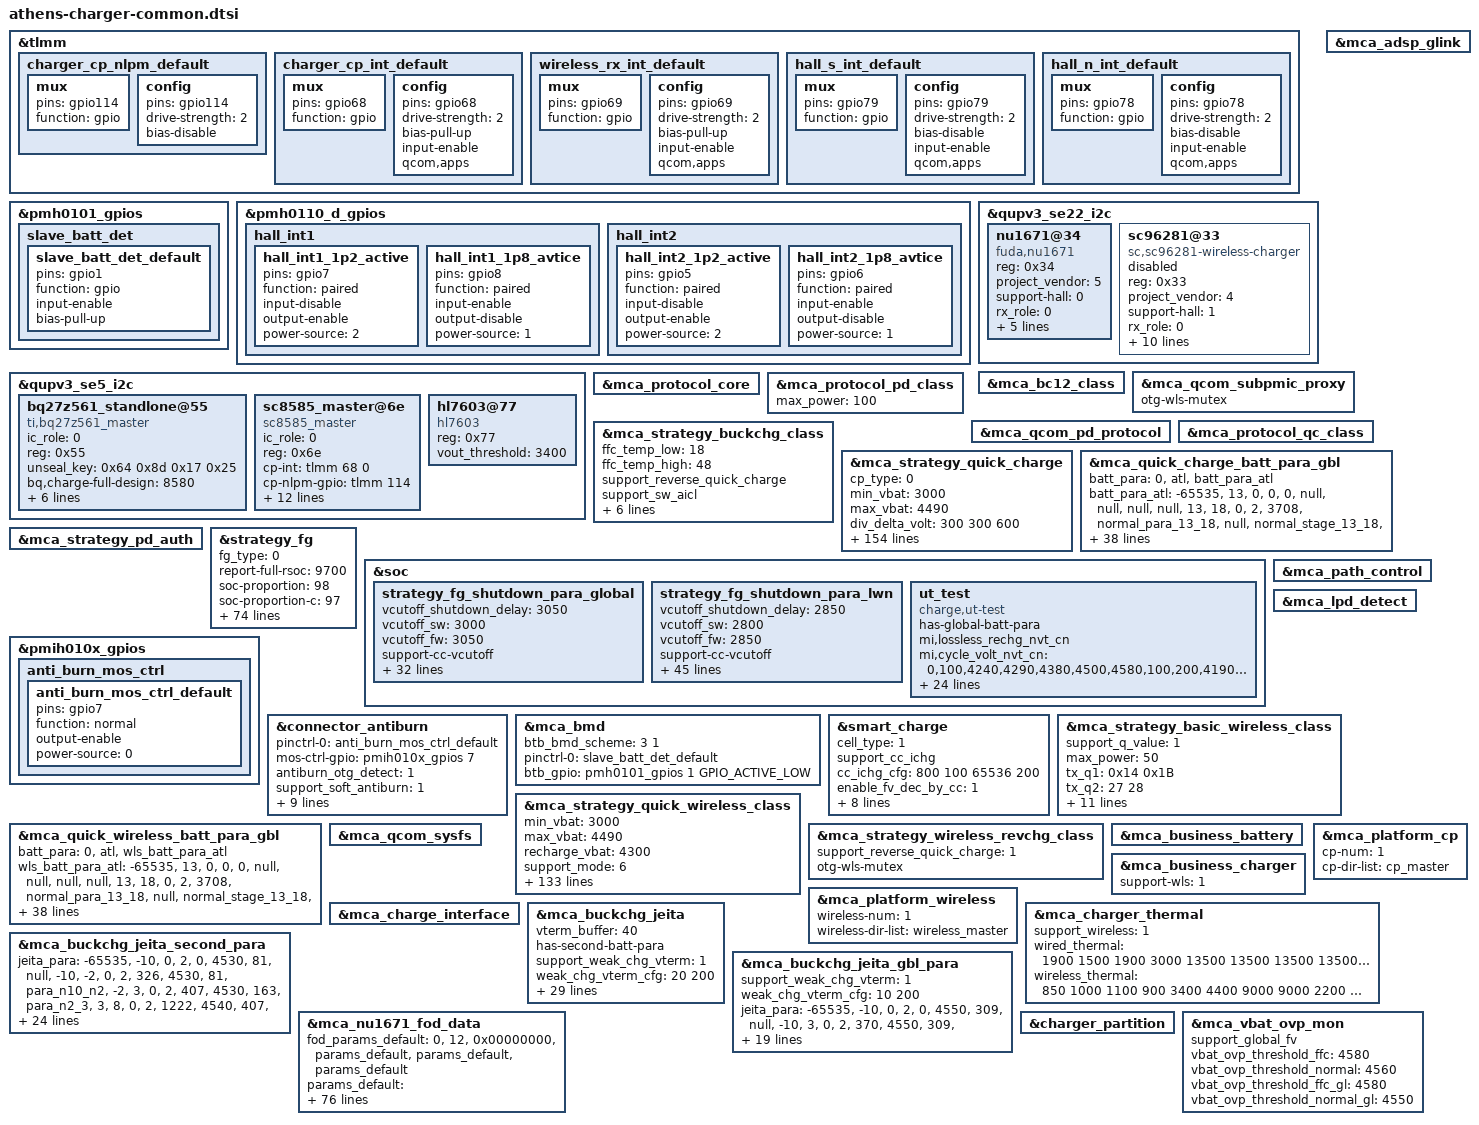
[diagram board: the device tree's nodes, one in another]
#include "mca.dtsi"

&tlmm {
	charger_cp_nlpm_default: charger_cp_nlpm_default {
		mux {
			pins = "gpio114";
			function = "gpio";
		};
		config {
			pins = "gpio114";
			drive-strength = <2>;   /* 2 mA */
			bias-disable;
		};
	};

	charger_cp_int_default: charger_cp_int_default {
		mux {
			pins = "gpio68";
			function = "gpio";
		};
		config {
			pins = "gpio68";
			drive-strength = <2>;   /* 2 mA */
			bias-pull-up;
			input-enable;
			qcom,apps;
		};
	};

	wireless_rx_int_default: wireless_rx_int_default {
		mux {
			pins = "gpio69";
			function = "gpio";
		};

		config {
			pins = "gpio69";
			drive-strength = <2>;
			bias-pull-up;
			input-enable;
			qcom,apps;
		};
	};

	hall_s_int_default: hall_s_int_default {
		mux {
			pins = "gpio79";
			function = "gpio";
		};

		config {
			pins = "gpio79";
			drive-strength = <2>;
			bias-disable;
			input-enable;
			qcom,apps;
		};
	};

	hall_n_int_default: hall_n_int_default {
		mux {
			pins = "gpio78";
			function = "gpio";
		};

		config {
			pins = "gpio78";
			drive-strength = <2>;
			bias-disable;
			input-enable;
			qcom,apps;
		};
	};

};

&pmh0101_gpios {
	slave_batt_det {
		slave_batt_det_default: slave_batt_det_default {
			pins = "gpio1";
			function = "gpio";
			input-enable;
			bias-pull-up;
		};
	};
};

&pmh0110_d_gpios {
	hall_int1 {
		hall_int1_1p2_active: hall_int1_1p2_active {
			pins = "gpio7";
			function = "paired";
			input-disable;
			output-enable;
			power-source = <2>; /* 1.2v */
		};

		hall_int1_1p8_avtice:hall_int1_1p8_avtice {
			pins = "gpio8";
			function = "paired";
			input-enable;
			output-disable;
			power-source = <1>; /* 1.8v */
		};
	};

	hall_int2 {
		hall_int2_1p2_active: hall_int2_1p2_active {
			pins = "gpio5";
			function = "paired";
			input-disable;
			output-enable;
			power-source = <2>; /* 1.2v */
		};

		hall_int2_1p8_avtice:hall_int2_1p8_avtice {
			pins = "gpio6";
			function = "paired";
			input-enable;
			output-disable;
			power-source = <1>; /* 1.8v */
		};
	};
};


&qupv3_se5_i2c {
	status = "ok";
	#address-cells = <1>;
	#size-cells = <0>;
	bq27z561_standlone@55 {
		compatible = "ti,bq27z561_master";
		ic_role = <0>;
		reg = <0x55>;
		unseal_key = /bits/ 8 <0x64 0x8d 0x17 0x25>;
		bq,charge-full-design = <8580>;
		soh_th = <92>;
		cycle_th = <400>;
		cycle_step = <50>;
		resistance-id = <100000>;
		support_batt_manager_4p0;
		support-batt-sn-v2026;
		status = "ok";
	};

	sc8585_master@6e {
		compatible = "sc8585_master";
		status = "ok";
		ic_role = <0>;
		reg = <0x6e>;
		cp-int= <&tlmm 68 0>;
		cp-nlpm-gpio = <&tlmm 114 0x00>;
		pinctrl-names = "default";
		pinctrl-0 = <&charger_cp_nlpm_default>, <&charger_cp_int_default>;
		bat-ovp-threshold = <4700>;
		bat-ovp-alarm-threshold = <4650>;
		bus-ovp-threshold = <21000 12000 6000>;
		usb-ovp-threshold = <21000 14000 7500>;
		bus-ocp-threshold = <5000 5500 5000>;
		wpc-ovp-threshold = <21000>;
		out-ovp-threshold = <5000>;
		pmid2-uvp-threshold = <150 350 100>;
		pmid2-ovp-threshold = <600>;
		ucp-fall-dg = <32000>;
	};

	hl7603@77 {
		compatible = "hl7603";
		reg = <0x77>;
		vout_threshold = <3400>;
	};
};

&qupv3_se22_i2c {
	status = "ok";
	#address-cells = <1>;
	#size-cells = <0>;

	nu1671@34 {
		compatible = "fuda,nu1671";
		reg = <0x34>;
		project_vendor = <5>;
		support-hall = <0>;
		rx_role = <0>;
		fw_version_index = <3>;
		pinctrl-names = "default";
		pinctrl-0 = <&wireless_rx_int_default>;
		rx-int = <&tlmm 69 0x00>;
		pwr-det-int = <&tlmm 57 0x00>;
		sleep-rx-gpio = <&tlmm 200 0x00>;
	};

	sc96281@33 {
		status = "disabled";
		compatible = "sc,sc96281-wireless-charger";
		reg = <0x33>;
		project_vendor = <4>;
		support-hall = <1>;
		rx_role = <0>;
		fw_version_index = <1>;
		pinctrl-names = "default";
		pinctrl-0 = <&wireless_rx_int_default>, <&hall_s_int_default>, <&hall_n_int_default>,
					<&hall_int1_1p2_active>, <&hall_int1_1p8_avtice>,
					<&hall_int2_1p2_active>, <&hall_int2_1p8_avtice>;
		rx-int = <&tlmm 69 0x00>;
		pwr-det-int = <&tlmm 57 0x00>;
		sleep-rx-gpio = <&tlmm 200 0x00>;
		hall-s-int = <&tlmm 79 0x00>;
		hall-n-int = <&tlmm 78 0x00>;
	};
};

&mca_adsp_glink {
	status = "ok";
};

&mca_bc12_class {
	status = "ok";
};

&mca_qcom_subpmic_proxy {
	status = "ok";
	otg-wls-mutex;
};

&mca_protocol_core {
	status = "ok";
};

&mca_protocol_pd_class {
	status = "ok";
	max_power = <100>;
};

&mca_qcom_pd_protocol {
	status = "ok";
};

&mca_protocol_qc_class {
	status = "ok";
};


&mca_strategy_buckchg_class {
	status = "ok";
	ffc_temp_low = <18>;
	ffc_temp_high = <48>;
	support_reverse_quick_charge;
	support_sw_aicl;
	support_revchg_screenon;
	support_pps_100w = <3>;
	support_revchg_27w;
	revchg_soc_thr = <60>;
	/* BS(Battery Sense) Vacc enable. Params inherited from mca.dtsi. */
	support_pmic_vacc;
	ffc_terminated_by_cp = <1>;
};

&mca_strategy_quick_charge {
	status = "ok";
	cp_type = <0>;
	min_vbat = <3000>;
	max_vbat = <4490>;
	div_delta_volt = <300 300 600>;
	div_single_curr = <4500 11000 18400>;
	div_max_curr = <5000 12000 18400>;
	non_mi_pps_max_curr = <4500 11000 18400>;
	support_mode = <6>;
	has-global-batt-para;
	support_cp_vfc = <1>;
	real_curr_max = <17500>;
	support_monitor_current = <17600>;
	curr_monitor_time_s = <120>;
	support_cancel_compensation;
	max_vbat_threshold = <4580>;
	en_buck_parallel_chg = <1>;
	buck_icl_fcc_curr = <1000 3000>;
	buck_en_th = <13000 2500>;
	buck_dis_th = <13000 3850>;
	cp_switch_pmic_th = <1000>;
	drop_fv_value = <10>; /* BS strategy -10mv, drop fv value for BS */

	/* BS(Battery Sense) PMIC&CP dynamic parallel charging (wired) enable.
	 * Params (pdc_*, enable_cp_para_pdc, ...) inherited from mca.dtsi.
	 */
	drop_fv_cycle_pdc = <65535>;
	support_pmic_dynamic_chg;

	use-terminate-staged;
	curr_terminate_hys = <300>;
	terminate_staged_para =
		<110 1000>,
		<105 3000>;
	vfc_iout_fsw_map =
		"6000", "720",
		"0", "420";
	batt_depolarize_time_s = <60>;

	/* volt_ratio, cur_gap, vbat_gap, vstep_ratio */
	vstep_para =
		"1", "300", "2000", "0", "2",
		"2", "300", "2000", "0", "4",
		"4", "300", "8000", "0", "25",
		"4", "300", "4000", "20", "17",
		"4", "300", "2000", "10", "5",
		"4", "300", "1200", "10", "5",
		"4", "300", "800", "0", "2",
		"1", "800", "2000", "0", "2",
		"2", "800", "2000", "0", "4",
		"4", "800", "8000", "0", "10",
		"4", "800", "6000", "0", "5",
		"4", "800", "4000", "0", "2";

	batt_para =
		"0", "atl", "batt_para_atl",
		"0", "lwn", "batt_para_lwn";
	/* temp_low, temp_high, low_hys, high_hys, max_curr, normal_para, ffc_para, normal_stage, ffc_stage */
	batt_para_atl =
		"-65535", "13", "0", "0", "0", "null", "null", "null", "null",
		"13", "15", "0", "1", "3258", "normal_para_atl_13_15", "null", "normal_stage_atl_13_15", "null",
		"15", "18", "0", "1", "8960", "normal_para_atl_15_18", "null", "null", "null",
		"18", "23", "0", "1", "12218", "normal_para_atl_18_23", "ffc_para_atl_18_23", "normal_stage_atl_18_23", "ffc_stage_atl_18_23",
		"23", "25", "0", "0", "18300", "normal_para_atl_23_25", "ffc_para_atl_23_25", "normal_stage_atl_18_23", "ffc_stage_atl_23_25",
		"25", "35", "0", "0", "18300", "normal_para_atl_25_35", "ffc_para_atl_25_35", "normal_stage_atl_18_23", "ffc_stage_atl_25_35",
		"35", "40", "1", "0", "18300", "normal_para_atl_35_40", "ffc_para_atl_35_40", "normal_stage_atl_18_23", "ffc_stage_atl_35_40",
		"40", "48", "1", "0", "18300", "normal_para_atl_40_48", "ffc_para_atl_40_48", "normal_stage_atl_18_23", "ffc_stage_atl_40_48",
		"48", "65535", "2", "0", "0", "null", "null", "null", "null";

	/* volt, curr_max, curr_min */
	normal_para_atl_13_15 =
		"3900", "3258", "1629",
		"4553", "1629", "407";
	normal_stage_atl_13_15 = <0 1 0 0>;

	normal_para_atl_15_18 =
		"3900", "8960", "6516",
		"4150", "6516", "3258",
		"4250", "3258", "1629",
		"4553", "1629", "407";

	normal_para_atl_18_23 =
		"3900", "12218", "8960",
		"4000", "8960", "6516",
		"4150", "6516", "3258",
		"4250", "3258", "1629",
		"4543", "1629", "407";
	normal_stage_atl_18_23 = <0 1 0 0 0 0 0 0 0 0>;
	ffc_para_atl_18_23 =
		"3900", "12218", "8960",
		"4000", "8960", "6516",
		"4150", "6516", "3258",
		"4250", "3258", "1629",
		"4570", "1629", "781";
	ffc_stage_atl_18_23 = <0 1 0 0 0 0 0 0 0 0>;

	normal_para_atl_23_25 =
		"4240", "18300", "12400",
		"4290", "12400", "8145",
		"4350", "8145", "6516",
		"4450", "6516", "4887",
		"4543", "4887", "407";
	ffc_para_atl_23_25 =
		"4240", "18300", "12400",
		"4290", "12400", "8145",
		"4350", "8145", "6516",
		"4450", "6516", "4887",
		"4570", "4887", "1064";
	ffc_stage_atl_23_25 = <0 1 0 0 0 0 0 0 0 0>;

	normal_para_atl_25_35 =
		"4240", "18300", "12400",
		"4290", "12400", "9774",
		"4380", "9774", "8145",
		"4480", "8145", "6516",
		"4543", "6516", "407";
	ffc_para_atl_25_35 =
		"4240", "18300", "12400",
		"4290", "12400", "9774",
		"4380", "9774", "8145",
		"4500", "8145", "6516",
		"4570", "6516", "1064";
	ffc_stage_atl_25_35 = <0 1 0 0 0 0 0 0 0 0>;

	normal_para_atl_35_40 =
		"4240", "18300", "12400",
		"4290", "12400", "9774",
		"4380", "9774", "8145",
		"4480", "8145", "6516",
		"4513", "6516", "407";
	ffc_para_atl_35_40 =
		"4240", "18300", "12400",
		"4290", "12400", "9774",
		"4380", "9774", "8145",
		"4500", "8145", "6516",
		"4570", "6516", "1751";
	ffc_stage_atl_35_40 = <0 1 0 0 0 0 0 0 0 0>;

	normal_para_atl_40_48 =
		"4240", "18300", "12400",
		"4290", "12400", "9774",
		"4380", "9774", "8145",
		"4480", "8145", "6516",
		"4503", "6516", "407";
	ffc_para_atl_40_48 =
		"4240", "18300", "12400",
		"4290", "12400", "9774",
		"4380", "9774", "8145",
		"4500", "8145", "6516",
		"4570", "6516", "3043";
	ffc_stage_atl_40_48 = <0 1 0 0 0 0 0 0 0 0>;

	batt_para_lwn =
		"-65535", "13", "0", "0", "0", "null", "null", "null", "null",
		"13", "15", "0", "1", "3258", "normal_para_lwn_13_15", "null", "normal_stage_lwn_13_15", "null",
		"15", "18", "0", "1", "8960", "normal_para_lwn_15_18", "null", "null", "null",
		"18", "23", "0", "1", "12218", "normal_para_lwn_18_23", "ffc_para_lwn_18_23", "normal_stage_lwn_18_23", "ffc_stage_lwn_18_23",
		"23", "25", "0", "0", "18300", "normal_para_lwn_23_25", "ffc_para_lwn_23_25", "normal_stage_lwn_18_23", "ffc_stage_lwn_23_25",
		"25", "35", "0", "0", "18300", "normal_para_lwn_25_35", "ffc_para_lwn_25_35", "normal_stage_lwn_18_23", "ffc_stage_lwn_25_35",
		"35", "40", "1", "0", "18300", "normal_para_lwn_35_40", "ffc_para_lwn_35_40", "normal_stage_lwn_18_23", "ffc_stage_lwn_35_40",
		"40", "48", "1", "0", "18300", "normal_para_lwn_40_48", "ffc_para_lwn_40_48", "normal_stage_lwn_18_23", "ffc_stage_lwn_40_48",
		"48", "65535", "2", "0", "0", "null", "null", "null", "null";
	/* volt, curr_max, curr_min */
	normal_para_lwn_13_15 =
		"3900", "3258", "1629",
		"4533", "1629", "407";
	normal_stage_lwn_13_15 = <0 1 0 0>;

	normal_para_lwn_15_18 =
		"3900", "8960", "6516",
		"4150", "6516", "3258",
		"4250", "3258", "1629",
		"4533", "1629", "407";

	normal_para_lwn_18_23 =
		"3900", "12218", "8960",
		"4000", "8960", "6516",
		"4150", "6516", "3258",
		"4250", "3258", "1629",
		"4513", "1629", "407";
	normal_stage_lwn_18_23 = <0 1 0 0 0 0 0 0 0 0>;
	ffc_para_lwn_18_23 =
		"3900", "12218", "8960",
		"4000", "8960", "6516",
		"4150", "6516", "3258",
		"4250", "3258", "1629",
		"4560", "1629", "977";
	ffc_stage_lwn_18_23 = <0 1 0 0 0 0 0 0 0 0>;

	normal_para_lwn_23_25 =
		"4190", "18300", "12400",
		"4270", "12400", "8145",
		"4350", "8145", "6516",
		"4500", "6516", "4887",
		"4513", "4887", "407";
	ffc_para_lwn_23_25 =
		"4190", "18300", "12400",
		"4270", "12400", "8145",
		"4350", "8145", "6516",
		"4500", "6516", "4887",
		"4560", "4887", "1140";
	ffc_stage_lwn_23_25 = <0 1 0 0 0 0 0 0 0 0>;

	normal_para_lwn_25_35 =
		"4190", "18300", "12400",
		"4270", "12400", "9774",
		"4350", "9774", "8145",
		"4500", "8145", "6516",
		"4513", "6516", "407";
	ffc_para_lwn_25_35 =
		"4190", "18300", "12400",
		"4270", "12400", "9774",
		"4350", "9774", "8145",
		"4500", "8145", "6516",
		"4560", "6516", "1140";
	ffc_stage_lwn_25_35 = <0 1 0 0 0 0 0 0 0 0>;

	normal_para_lwn_35_40 =
		"4190", "18300", "12400",
		"4270", "12400", "9774",
		"4350", "9774", "8145",
		"4480", "8145", "6516",
		"4493", "6516", "407";
	ffc_para_lwn_35_40 =
		"4190", "18300", "12400",
		"4270", "12400", "9774",
		"4350", "9774", "8145",
		"4500", "8145", "6516",
		"4560", "6516", "1792";
	ffc_stage_lwn_35_40 = <0 1 0 0 0 0 0 0 0 0>;

	normal_para_lwn_40_48 =
		"4190", "18300", "12400",
		"4270", "12400", "9774",
		"4350", "9774", "8145",
		"4470", "8145", "6516",
		"4483", "6516", "407";
	ffc_para_lwn_40_48 =
		"4190", "18300", "12400",
		"4270", "12400", "9774",
		"4350", "9774", "8145",
		"4500", "8145", "6516",
		"4560", "6516", "3095";
	ffc_stage_lwn_40_48 = <0 1 0 0 0 0 0 0 0 0>;
};

&mca_quick_charge_batt_para_gbl {
	batt_para =
		"0", "atl", "batt_para_atl";
	/* temp_low, temp_high, low_hys, high_hys, max_curr, normal_para, ffc_para, normal_stage, ffc_stage */
	batt_para_atl =
		"-65535", "13", "0", "0", "0", "null", "null", "null", "null",
		"13", "18", "0", "2", "3708", "normal_para_13_18", "null", "normal_stage_13_18", "null",
		"18", "23", "0", "1", "12360", "normal_para_18_23", "ffc_para_18_23", "normal_stage_13_18", "ffc_stage_18_23",
		"23", "35", "0", "0", "18100", "normal_para_23_35", "ffc_para_23_35", "normal_stage_13_18", "ffc_stage_23_35",
		"35", "40", "1", "0", "18100", "normal_para_35_40", "ffc_para_35_40", "normal_stage_13_18", "ffc_stage_35_40",
		"40", "48", "1", "0", "18100", "normal_para_40_48", "ffc_para_40_48", "normal_stage_13_18", "ffc_stage_40_48",
		"48", "65535", "2", "0", "0", "null", "null", "null", "null";

	/* volt, curr_max, curr_min */
	normal_para_13_18 =
		"4200", "3708", "2472",
		"4543", "2472", "432";
	normal_stage_13_18 = <0 1 0 0>;

	normal_para_18_23 =
		"4250", "12360", "7416",
		"4523", "7416", "432";
	ffc_para_18_23 =
		"4250", "12360", "9270",
		"4500", "9270", "7416",
		"4573", "7416", "1050";
	ffc_stage_18_23 = <0 1 0 0 0 0>;

	normal_para_23_35 =
		"4230", "18100", "7416",
		"4523", "7416", "432";
	ffc_para_23_35 =
		"4230", "18100", "12400",
		"4330", "12400", "11124",
		"4400", "11124", "9270",
		"4500", "9270", "7416",
		"4573", "7416", "1668";
	ffc_stage_23_35 = <0 1 0 0 0 0 0 0 0 0>;

	normal_para_35_40 =
		"4230", "18100", "7416",
		"4513", "7416", "432";
	ffc_para_35_40 =
		"4230", "18100", "12400",
		"4330", "12400", "11124",
		"4400", "11124", "9270",
		"4500", "9270", "7416",
		"4573", "7416", "2720";
	ffc_stage_35_40 = <0 1 0 0 0 0 0 0 0 0>;

	normal_para_40_48 =
		"4230", "18100", "7416",
		"4503", "7416", "432";
	ffc_para_40_48 =
		"4230", "18100", "12400",
		"4330", "12400", "11124",
		"4400", "11124", "9270",
		"4500", "9270", "7416",
		"4573", "7416", "4264";
	ffc_stage_40_48 = <0 1 0 0 0 0 0 0 0 0>;
};

&mca_strategy_pd_auth {
	status = "ok";
};

&strategy_fg {
	status = "ok";
	fg_type = <0>;
	report-full-rsoc = <9700>;
	soc-proportion = <98>;
	soc-proportion-c = <97>;
	support-pnc;
	support-vpack-low-shutdown;
	has_global_shutdown_para;
	has_second_supplier_para;
	vcutoff_shutdown_delay = <2850>;
	vcutoff_sw = <2800>;
	vcutoff_fw = <2850>;
	vterm_delta = <7>;
	clear_CC_per_hundred = <0>;

	/* BS(Battery Sense) Vacc + CP dynamic enable. Params inherited from mca.dtsi. */
	support_pmic_vacc;
	support_pmic_cp_dynamic;

	support-cc-vcutoff;
	/* temp_low, temp_high, low_temp_hys, high_temp_hys, vterm_para_name */
	cc_vcutoff_cfg =
		"-65535", "-6", "0", "2", "cc_para0",
		"-6", "0", "2", "2", "cc_para1",
		"0", "10", "2", "2", "cc_para2",
		"10", "60", "2", "0", "cc_para3",
		"60", "65535", "2", "0", "cc_para4";
	/* cycle_count, vterm_fw, vterm_shutdown_delay, vempty */
	cc_para0 =
		"300", "2650", "2600", "2500",
		"500", "2650", "2600", "2550",
		"1100", "2750", "2700", "2650",
		"1300", "3000", "2950", "2900",
		"65535", "3050", "3000", "2950";
	cc_para1 =
		"300", "2650", "2600", "2550",
		"500", "2750", "2700", "2650",
		"1100", "2850", "2800", "2750",
		"1300", "3050", "3000", "2950",
		"65535", "3100", "3050", "3000";
	cc_para2 =
		"300", "2650", "2650", "2600",
		"500", "2900", "2900", "2850",
		"1100", "2950", "2950", "2900",
		"1300", "3100", "3100", "3050",
		"65535", "3150", "3150", "3100";
	cc_para3 =
		"300", "2850", "2850", "2800",
		"500", "3010", "3010", "2960",
		"1100", "3070", "3070", "3020",
		"1300", "3200", "3200", "3150",
		"65535", "3230", "3230", "3180";
	cc_para4 =
		"65535", "3230", "3230", "3180";

	support-dod-vcutoff-v2;
	weight = <17 13 10>;
	/* temp_low, temp_high, low_temp_hys, high_temp_hys, vterm_para_name */
	dod_vcutoff_cfg =
		"-65535", "-6", "0", "2", "dod_para0",
		"-6", "0", "2", "2", "dod_para1",
		"0", "10", "2", "2", "dod_para2",
		"10", "60", "2", "0", "dod_para3",
		"60", "65535", "2", "0", "dod_para4";
	/* dod_count, vterm_fw, vterm_shutdown_delay, vempty */
	dod_para0 =
		"187", "2650", "2600", "2500",
		"363", "2650", "2600", "2550",
		"671", "2750", "2700", "2650",
		"825", "3000", "2950", "2900",
		"65535", "3050", "3000", "2950";
	dod_para1 =
		"187", "2650", "2600", "2550",
		"363", "2750", "2700", "2650",
		"671", "2850", "2800", "2750",
		"825", "3050", "3000", "2950",
		"65535", "3050", "3000", "2950";
	dod_para2 =
		"187", "2650", "2650", "2600",
		"363", "2900", "2900", "2850",
		"671", "2950", "2950", "2900",
		"825", "3100", "3100", "3050",
		"65535", "3100", "3100", "3050";
	dod_para3 =
		"187", "2850", "2850", "2800",
		"363", "3010", "3010", "2960",
		"671", "3070", "3070", "3020",
		"825", "3200", "3200", "3150",
		"65535", "3230", "3230", "3180";
	dod_para4 =
		"65535", "3230", "3230", "3180";

	adapt_power = <100>;
	model-name = "Q11_8580mah_100w";
	model-name-global = "Q11_6330mah_100w";
	support_full_design_gl;
	charge-full-design = <8580>;
	support_dynamic_capacity_comp;
	support_dtpt = <1>;
	charge-full-design-gl = <6330>;
	fg_hightemp_vterm = <4200>;
	support-lossless-rechg = <1>;
	lossless_rechg_cfg = <18 47 300>;
	lossless-rechg-nor = <0>;
	support_normal_force_full;
	normal_force_full_hys = <116>;
	support_clear_cycle;
	suppot_RSOC_0_smooth = <1>;
	smooth_temp_unit = <0 150>; //15℃
	smooth_curr_unit = <0 300000 600000 1000000 >;
	smooth_vol_offset = <0x80000000 0 100 200 300 >;
	dischg_smooth_low_temp_unit = <
		10 10 10 10
		20 10 10 10
		40 20 10 10
		80 40 30 20
		150 80 70 50 >;
	dischg_smooth_high_temp_unit = <
		10 10 10 10
		30 20 10 10
		60 40 20 10
		150 70 50 40
		200 150 100 70 >;
	support_extreme_cold = <2>;
	extreme_cold_temp_compemsation =
		"2147483647", "50", "100",
		"2147483647", "600", "80";
};

&soc {
	strategy_fg_shutdown_para_global {
		vcutoff_shutdown_delay = <3050>;
		vcutoff_sw = <3000>;
		vcutoff_fw = <3050>;
		support-cc-vcutoff;
		/* temp_low, temp_high, low_temp_hys, high_temp_hys, vterm_para_name */
		cc_vcutoff_cfg =
			"-65535", "-6", "0", "2", "cc_para0",
			"-6", "0", "2", "2", "cc_para1",
			"0", "10", "2", "2", "cc_para2",
			"10", "60", "2", "0", "cc_para3",
			"60", "65535", "2", "0", "cc_para4";
		/* cycle_count, vterm_fw, vterm_shutdown_delay, vempty */
		cc_para0 =
			"800", "2900", "2850", "2800",
			"1200", "2900", "2850", "2800",
			"65535", "2900", "2850","2800";
		cc_para1 =
			"800", "2900", "2850", "2800",
			"1200", "2900", "2850", "2800",
			"65535", "3000", "2950","2900";
		cc_para2 =
			"800", "2900", "2900", "2850",
			"1200", "3000", "3000", "2950",
			"65535", "3050", "3050","3000";
		cc_para3 =
			"800", "3050", "3050", "3000",
			"1200", "3120", "3120", "3070",
			"65535", "3200", "3200","3150";
		cc_para4 =
			"65535", "3200", "3200","3150";
		support-dod-vcutoff-v2;
		weight = <20 18 15>;
		/* temp_low, temp_high, low_temp_hys, high_temp_hys, vterm_para_name */
		dod_vcutoff_cfg =
			"-65535", "-6", "0", "2", "dod_para0",
			"-6", "0", "2", "2", "dod_para1",
			"0", "10", "2", "2", "dod_para2",
			"10", "60", "2", "0", "dod_para3",
			"60", "65535", "2", "0", "dod_para4";
		/* dod_count, vterm_fw, vterm_shutdown_delay, vempty */
		dod_para0 =
			"169", "2900", "2850", "2800",
			"452", "2900", "2850", "2800",
			"1051", "2900", "2850", "2800",
			"65535", "3000", "2950", "2900";
		dod_para1 =
			"169", "2900", "2850", "2800",
			"452", "2900", "2850", "2800",
			"1051", "3000", "2950", "2900",
			"65535", "3050", "3000", "2950";
		dod_para2 =
			"169", "2900", "2900", "2850",
			"452", "3000", "3000", "2950",
			"1051", "3050", "3050", "3000",
			"65535", "3150", "3150", "3100";
		dod_para3 =
			"169", "3050", "3050", "3000",
			"452", "3120", "3120", "3070",
			"1051", "3200", "3200", "3150",
			"65535", "3250", "3250", "3200";
		dod_para4 =
			"65535", "3250", "3250", "3200";
	};

	strategy_fg_shutdown_para_lwn {
		vcutoff_shutdown_delay = <2850>;
		vcutoff_sw = <2800>;
		vcutoff_fw = <2850>;
		support-cc-vcutoff;
		cc_vcutoff_cfg =
			"-65535", "-6", "0", "2", "cc_para0_lwn",
			"-6", "0", "2", "2", "cc_para1_lwn",
			"0", "10", "2", "2", "cc_para2_lwn",
			"10", "60", "2", "0", "cc_para3_lwn",
			"60", "65535", "2", "0", "cc_para4_lwn";
		cc_para0_lwn =
			"300", "2600", "2550", "2500",
			"500", "2650", "2600", "2550",
			"1100", "2750", "2700", "2650",
			"1300", "2800", "2750", "2700",
			"65535", "3000", "2950", "2900";
		cc_para1_lwn =
			"300", "2650", "2600", "2550",
			"500", "2750", "2700", "2650",
			"1100", "2850", "2800", "2750",
			"1300", "2900", "2850", "2800",
			"65535", "3050", "3000", "3050";
		cc_para2_lwn =
			"300", "2700", "2700", "2650",
			"500", "2850", "2850", "2800",
			"1100", "2950", "2950", "2900",
			"1300", "3000", "3000", "2950",
			"65535", "3150", "3150", "3050";
		cc_para3_lwn =
			"300", "2850", "2850", "2800",
			"500", "3010", "3010", "2960",
			"1100", "3080", "3080", "3030",
			"1300", "3160", "3160", "3110",
			"65535", "3210", "3210", "3160";
		cc_para4_lwn =
			"65535", "3210", "3210", "3160";
		support-dod-vcutoff-v2;
		weight = <21 19 15>;
		dod_vcutoff_cfg =
			"-65535", "-6", "0", "2", "dod_para0_lwn",
			"-6", "0", "2", "2", "dod_para1_lwn",
			"0", "10", "2", "2", "dod_para2_lwn",
			"10", "60", "2", "0", "dod_para3_lwn",
			"60", "65535", "2", "0", "dod_para4_lwn";
		dod_para0_lwn =
			"59", "2600", "2550", "2500",
			"152", "2650", "2600", "2550",
			"718", "2750", "2700", "2650",
			"1370", "2800", "2750", "2700",
			"65535", "3000", "2950", "2900";
		dod_para1_lwn =
			"59", "2650", "2600", "2550",
			"152", "2750", "2700", "2650",
			"718", "2850", "2800", "2750",
			"1370", "2900", "2850", "2800",
			"65535", "3050", "3000", "2950";
		dod_para2_lwn =
			"59", "2700", "2700", "2650",
			"152", "2850", "2850", "2800",
			"718", "2950", "2950", "2900",
			"1370", "3000", "3000", "2950",
			"65535", "3150", "3150", "3050";
		dod_para3_lwn =
			"59", "2850", "2850", "2800",
			"152", "3010", "3010", "2960",
			"718", "3080", "3080", "3030",
			"1370", "3160", "3160", "3110",
			"65535", "3210", "3210", "3160";
		dod_para4_lwn =
			"65535", "3210", "3210", "3160";
	};
};

&pmih010x_gpios {
	anti_burn_mos_ctrl {
		anti_burn_mos_ctrl_default: anti_burn_mos_ctrl_default {
			pins = "gpio7";
			function = "normal";
			output-enable;
			//drive-strength = <2>;
			power-source = <0>;
		};
	};
};

&connector_antiburn {
	status = "ok";
	pinctrl-names = "default";
	pinctrl-0 = <&anti_burn_mos_ctrl_default>;
	mos-ctrl-gpio = <&pmih010x_gpios 7 0>;
	antiburn_otg_detect = <1>;
	support_soft_antiburn = <1>;
	support_hw_antiburn = <1>;
	use_double_ntc = <1>;
	monitor_interval = <1000>;
	thermal-zone-name = "conn_therm";
	thermal-zone-name2 = "conn_therm2";
	max_temp_increase_rate = <4>; /*ntc temperature increase speed per second.*/
	otg_boost_src = <0>; /* BOOST_SRC_EXTERNAL */
	en_src = <0>; /* OTG_EN_BOOST */
	thermal-board-temp-name = "board_sensor_therm";
};

&mca_bmd {
	status = "ok";
	btb_bmd_scheme = <3 1>;
	pinctrl-names = "default";
	pinctrl-0 = <&slave_batt_det_default>;
	btb_gpio = <&pmh0101_gpios 1 GPIO_ACTIVE_LOW>;
};

&smart_charge {
	status = "ok";
	cell_type = <1>;
	support_cc_ichg;
	/* cyclecount delta_ichg*/
	cc_ichg_cfg = <
		800 100
		65536 200>;
	enable_fv_dec_by_cc = <1>;
	smart_bypass_support = <1>;
	smart_bypass_entry_soc = <40>;
	smart_bypass_high_lmt_cfg = <
		(-100) 150 5 5 4500
		151 200 5 5 4500
		201	250	5 5 4500
		251	300	5 5 3500
		301	370	5 5 2500
		371	800	5 5 1000>;
	smart_bypass_med_lmt_cfg = <
		(-100) 150 5 5 18400
		151	200	5 5 18400
		201	250	5 5 18400
		251	300	5 5 8000
		301	370	5 5 5000
		371	800	5 5 2000>;
	smart_bypass_low_lmt_cfg = <
		(-100) 150 5 5 18400
		151	200	5 5 18400
		201	250	5 5 18400
		251	300	5 5 9000
		301	370	5 5 5000
		371	800	5 5 3000>;
};

&mca_path_control {
	status = "ok";
};

&mca_lpd_detect {
	status = "ok";
};

&mca_strategy_basic_wireless_class {
	status = "ok";
	support_q_value = <1>;
	max_power = <50>;
	/* low_inductance_tx_50w, low_inductance_tx_80w */
	tx_q1 = /bits/ 8 <0x14 0x1B>;
	tx_q2 = <27 28>;
	rx_max_iout = <2650 2650>;
	wls_vdd_src = <4>;
	ffc_temp_low = <15>;
	ffc_temp_high = <48>;
	support-hall = <0>;

	support-dynamic-cp = <1>;
	dynamic-cp-uuid = <0x09010A01>;
	dynamic-cp-min-tx-adapter = <14>;
	dynamic-cp-4to2-threshold = <6000>;
	dynamic-cp-2-1-max-fcc = <9200>;

	/* BS(Battery Sense) Vacc for wireless. */
	support_pmic_vacc;
};

&mca_strategy_quick_wireless_class {
	status = "ok";
	min_vbat = <3000>;
	max_vbat = <4490>;
	recharge_vbat = <4300>;
	support_mode = <6>;
	div_single_curr = <0 9200 9200>;
	div_max_curr = <0 9200 9200>;
	has-global-batt-para;
	support-hall = <0>;
	exit_fcc = <1000 1500 1500>;

	/* BS(Battery Sense) PMIC&CP dynamic parallel charging (wireless) enable.
	 * Params (exit_fcc, pdc_*, cp_ovp_spec_pdc, ...) inherited from mca.dtsi.
	 */
	support_pmic_dynamic_chg;

	batt_para =
		"0", "atl", "wls_batt_para_atl",
		"0", "lwn", "wls_batt_para_lwn";
	/* temp_low, temp_high, low_temp_hys, high_temp_hys, max_current, volt_para_name stage_para_name*/
	wls_batt_para_atl =
		"-65535", "13", "0", "0", "0", "null", "null", "null", "null",
		"13", "15", "0", "1", "3258", "normal_para_atl_13_15", "null", "normal_stage_atl_13_15", "null",
		"15", "18", "0", "1", "8960", "normal_para_atl_15_18", "null", "null", "null",
		"18", "23", "0", "1", "12218", "normal_para_atl_18_23", "ffc_para_atl_18_23", "normal_stage_atl_18_23", "ffc_stage_atl_18_23",
		"23", "25", "0", "0", "17600", "normal_para_atl_23_25", "ffc_para_atl_23_25", "normal_stage_atl_18_23", "ffc_stage_atl_23_25",
		"25", "35", "0", "0", "17600", "normal_para_atl_25_35", "ffc_para_atl_25_35", "normal_stage_atl_18_23", "ffc_stage_atl_25_35",
		"35", "40", "1", "0", "17600", "normal_para_atl_35_40", "ffc_para_atl_35_40", "normal_stage_atl_18_23", "ffc_stage_atl_35_40",
		"40", "48", "1", "0", "17600", "normal_para_atl_40_48", "ffc_para_atl_40_48", "normal_stage_atl_18_23", "ffc_stage_atl_40_48",
		"48", "65535", "2", "0", "0", "null", "null", "null", "null";

	/* volt, curr_max, curr_min */
	normal_para_atl_13_15 =
		"3900", "3258", "1629",
		"4553", "1629", "407";
	normal_stage_atl_13_15 = <0 1 0 0>;

	normal_para_atl_15_18 =
		"3900", "8960", "6516",
		"4150", "6516", "3258",
		"4250", "3258", "1629",
		"4553", "1629", "407";

	normal_para_atl_18_23 =
		"3900", "12218", "8960",
		"4000", "8960", "6516",
		"4150", "6516", "3258",
		"4250", "3258", "1629",
		"4543", "1629", "407";
	normal_stage_atl_18_23 = <0 1 0 0 0 0 0 0 0 0>;
	ffc_para_atl_18_23 =
		"3900", "12218", "8960",
		"4000", "8960", "6516",
		"4150", "6516", "3258",
		"4250", "3258", "1629",
		"4540", "1629", "781";
	ffc_stage_atl_18_23 = <0 1 0 1 0 1 0 1 0 1>;

	normal_para_atl_23_25 =
		"4240", "17600", "12400",
		"4290", "12400", "8145",
		"4380", "8145", "6516",
		"4500", "6516", "4887",
		"4543", "4887", "407";
	ffc_para_atl_23_25 =
		"4240", "17600", "12400",
		"4290", "12400", "8145",
		"4380", "8145", "6516",
		"4500", "6516", "4887",
		"4540", "4887", "1064";
	ffc_stage_atl_23_25 = <0 1 0 1 0 1 0 1 0 1>;

	normal_para_atl_25_35 =
		"4240", "17600", "12400",
		"4290", "12400", "9774",
		"4380", "9774", "8145",
		"4500", "8145", "6516",
		"4543", "6516", "407";
	ffc_para_atl_25_35 =
		"4240", "17600", "12400",
		"4290", "12400", "9774",
		"4380", "9774", "8145",
		"4500", "8145", "6516",
		"4540", "6516", "1064";
	ffc_stage_atl_25_35 = <0 1 0 1 0 1 0 1 0 1>;

	normal_para_atl_35_40 =
		"4240", "17600", "12400",
		"4290", "12400", "9774",
		"4380", "9774", "8145",
		"4500", "8145", "6516",
		"4513", "6516", "407";
	ffc_para_atl_35_40 =
		"4240", "17600", "12400",
		"4290", "12400", "9774",
		"4380", "9774", "8145",
		"4500", "8145", "6516",
		"4510", "6516", "1751";
	ffc_stage_atl_35_40 = <0 1 0 1 0 1 0 1 0 1>;

	normal_para_atl_40_48 =
		"4240", "17600", "12400",
		"4290", "12400", "9774",
		"4380", "9774", "8145",
		"4500", "8145", "6516",
		"4503", "6516", "407";
	ffc_para_atl_40_48 =
		"4240", "17600", "12400",
		"4290", "12400", "9774",
		"4380", "9774", "6516",
		"4500", "6516", "3043";
	ffc_stage_atl_40_48 = <0 1 0 1 0 1 0 1 0 1>;

	wls_batt_para_lwn =
		"-65535", "13", "0", "0", "0", "null", "null", "null", "null",
		"13", "15", "0", "1", "3258", "normal_para_lwn_13_15", "null", "normal_stage_lwn_13_15", "null",
		"15", "18", "0", "1", "8960", "normal_para_lwn_15_18", "null", "null", "null",
		"18", "23", "0", "1", "12218", "normal_para_lwn_18_23", "ffc_para_lwn_18_23", "normal_stage_lwn_18_23", "ffc_stage_lwn_18_23",
		"23", "25", "0", "0", "17600", "normal_para_lwn_23_25", "ffc_para_lwn_23_25", "normal_stage_lwn_18_23", "ffc_stage_lwn_23_25",
		"25", "35", "0", "0", "17600", "normal_para_lwn_25_35", "ffc_para_lwn_25_35", "normal_stage_lwn_18_23", "ffc_stage_lwn_25_35",
		"35", "40", "1", "0", "17600", "normal_para_lwn_35_40", "ffc_para_lwn_35_40", "normal_stage_lwn_18_23", "ffc_stage_lwn_35_40",
		"40", "48", "1", "0", "17600", "normal_para_lwn_40_48", "ffc_para_lwn_40_48", "normal_stage_lwn_18_23", "ffc_stage_lwn_40_48",
		"48", "65535", "2", "0", "0", "null", "null", "null", "null";
	/* volt, curr_max, curr_min */
	normal_para_lwn_13_15 =
		"3900", "3258", "1629",
		"4533", "1629", "407";
	normal_stage_lwn_13_15 = <0 1 0 0>;

	normal_para_lwn_15_18 =
		"3900", "8960", "6516",
		"4150", "6516", "3258",
		"4250", "3258", "1629",
		"4533", "1629", "407";

	normal_para_lwn_18_23 =
		"3900", "12218", "8960",
		"4000", "8960", "6516",
		"4150", "6516", "3258",
		"4250", "3258", "1629",
		"4513", "1629", "407";
	normal_stage_lwn_18_23 = <0 1 0 0 0 0 0 0 0 0>;
	ffc_para_lwn_18_23 =
		"3900", "12218", "8960",
		"4000", "8960", "6516",
		"4150", "6516", "3258",
		"4250", "3258", "1629",
		"4510", "1629", "896";
	ffc_stage_lwn_18_23 = <0 1 0 1 0 1 0 1 0 1>;

	normal_para_lwn_23_25 =
		"4190", "17600", "12400",
		"4270", "12400", "8145",
		"4350", "8145", "6516",
		"4500", "6516", "4887",
		"4513", "4887", "407";
	ffc_para_lwn_23_25 =
		"4190", "17600", "12400",
		"4270", "12400", "8145",
		"4350", "8145", "6516",
		"4500", "6516", "4887",
		"4510", "4887", "1222";
	ffc_stage_lwn_23_25 = <0 1 0 1 0 1 0 1 0 1>;

	normal_para_lwn_25_35 =
		"4190", "17600", "12400",
		"4270", "12400", "9774",
		"4350", "9774", "8145",
		"4500", "8145", "6516",
		"4513", "6516", "407";
	ffc_para_lwn_25_35 =
		"4190", "17600", "12400",
		"4270", "12400", "9774",
		"4350", "9774", "8145",
		"4500", "8145", "6516",
		"4510", "6516", "1222";
	ffc_stage_lwn_25_35 = <0 1 0 1 0 1 0 1 0 1>;

	normal_para_lwn_35_40 =
		"4190", "17600", "12400",
		"4270", "12400", "9774",
		"4350", "9774", "8145",
		"4480", "8145", "6516",
		"4493", "6516", "407";
	ffc_para_lwn_35_40 =
		"4190", "17600", "12400",
		"4270", "12400", "9774",
		"4350", "9774", "6516",
		"4490", "6516", "1955";
	ffc_stage_lwn_35_40 = <0 1 0 1 0 1 0 1 0 1>;

	normal_para_lwn_40_48 =
		"4190", "17600", "12400",
		"4270", "12400", "9774",
		"4350", "9774", "8145",
		"4470", "8145", "6516",
		"4483", "6516", "407";
	ffc_para_lwn_40_48 =
		"4190", "17600", "12400",
		"4270", "12400", "9774",
		"4350", "9774", "6516",
		"4480", "6516", "3258";
	ffc_stage_lwn_40_48 = <0 1 0 1 0 1 0 1 0 1>;

	vstep_para =
		"1", "2000", "2",
		"2", "4000", "25",
		"2", "3000", "25",
		"2", "2000", "4",
		"4", "4000", "25",
		"4", "3000", "25",
		"4", "2000", "6",
		"4", "1000", "3",
		"4", "500", "2",
		"4", "200", "1";
};

&mca_quick_wireless_batt_para_gbl {
	batt_para =
		"0", "atl", "wls_batt_para_atl";
	/* temp_low, temp_high, low_temp_hys, high_temp_hys, max_current, volt_para_name stage_para_name*/
	wls_batt_para_atl =
		"-65535", "13", "0", "0", "0", "null", "null", "null", "null",
		"13", "18", "0", "2", "3708", "normal_para_13_18", "null", "normal_stage_13_18", "null",
		"18", "23", "0", "1", "12360", "normal_para_18_23", "ffc_para_18_23", "normal_stage_13_18", "ffc_stage_18_23",
		"23", "35", "0", "0", "17600", "normal_para_23_35", "ffc_para_23_35", "normal_stage_13_18", "ffc_stage_23_35",
		"35", "40", "1", "0", "17600", "normal_para_35_40", "ffc_para_35_40", "normal_stage_13_18", "ffc_stage_35_40",
		"40", "48", "1", "0", "17600", "normal_para_40_48", "ffc_para_40_48", "normal_stage_13_18", "ffc_stage_40_48",
		"48", "65535", "2", "0", "0", "null", "null", "null", "null";

	/* volt, curr_max, curr_min */
	normal_para_13_18 =
		"4200", "3708", "2472",
		"4543", "2472", "432";
	normal_stage_13_18 = <0 1 0 0>;

	normal_para_18_23 =
		"4250", "12360", "7416",
		"4523", "7416", "432";
	ffc_para_18_23 =
		"4250", "12360", "9270",
		"4500", "9270", "7416",
		"4573", "7416", "1050";
	ffc_stage_18_23 = <0 1 0 0 0 0>;

	normal_para_23_35 =
		"4230", "17600", "7416",
		"4523", "7416", "432";
	ffc_para_23_35 =
		"4230", "17600", "12400",
		"4330", "12400", "11124",
		"4400", "11124", "9270",
		"4500", "9270", "7416",
		"4573", "7416", "1668";
	ffc_stage_23_35 = <0 1 0 0 0 0 0 0 0 0>;

	normal_para_35_40 =
		"4230", "17600", "7416",
		"4513", "7416", "432";
	ffc_para_35_40 =
		"4230", "17600", "12400",
		"4330", "12400", "11124",
		"4400", "11124", "9270",
		"4500", "9270", "7416",
		"4573", "7416", "2720";
	ffc_stage_35_40 = <0 1 0 0 0 0 0 0 0 0>;

	normal_para_40_48 =
		"4230", "17600", "7416",
		"4503", "7416", "432";
	ffc_para_40_48 =
		"4230", "17600", "12400",
		"4330", "12400", "11124",
		"4400", "11124", "9270",
		"4500", "9270", "7416",
		"4573", "7416", "4264";
	ffc_stage_40_48 = <0 1 0 0 0 0 0 0 0 0>;
};

&mca_strategy_wireless_revchg_class {
	status = "ok";
	support_reverse_quick_charge = <1>;
	otg-wls-mutex;
};

&mca_qcom_sysfs {
	status = "ok";
};

&mca_business_battery {
	status = "ok";
};

&mca_business_charger {
	support-wls = <1>;
	status = "ok";
};

&mca_platform_cp {
	status = "ok";
	cp-num = <1>;
	cp-dir-list = "cp_master";
};

&mca_platform_wireless {
	status = "ok";
	wireless-num = <1>;
	wireless-dir-list = "wireless_master";
};

&mca_charge_interface {
	status = "ok";
};

&mca_charger_thermal {
	status = "ok";
	support_wireless = <1>;
	/* 5v_in 9v_in 5v_ichg 9v_ichg div1_single div1_multi div2_single div2_multi div4_single div4_multi*/
	wired_thermal = <
		1900 1500 1900 3000 13500 13500 13500 13500 13500 13500 /* level 1 */
		1900 1500 1900 3000 11000 11000 11000 11000 11000 11000 /* level 2 */
		1900 1500 1900 3000 9000  9000  9000  9000  9000  9000  /* level 3 */
		1900 1450 1900 3000 8000  8000  8000  8000  8000  8000  /* level 4 */
		1900 1400 1900 3000 7000  7000  7000  7000  7000  7000  /* level 5 */
		1900 1350 1900 2800 6000  6000  6000  6000  6000  6000  /* level 6 */
		1900 1300 1900 2600 5000  5000  5000  5000  5000  5000  /* level 7 */
		1900 1150 1900 2310 4000  4000  4000  4000  4000  4000  /* level 8 */
		1700 1100 1700 2200 3500  3500  3500  3500  3500  3500  /* level 9 */
		1600 1000 1600 2000 3000  3000  3000  3000  3000  3000  /* level 10 */
		1400 900  1500 2000 2500  2500  2500  2500  2500  2500  /* level 11 */
		1200 850  1500 2000 2000  2000  2000  2000  2000  2000  /* level 12 */
		1100 750  1500 1500 1500  1500  1500  1500  1500  1500  /* level 13 */
		1100 650  1000 1000 1000  1000  1000  1000  1000  1000  /* level 14 */
		1100 600  500  500  500   500   500   500   500   500   /* level 15 */
	>;
	/* bpp_in bpp_qc2 bpp_qc3 epp_in cp_20w cp_30w cp_50w cp_80w voice_box magnet_30w xiaomi_car */
	wireless_thermal = <
		850 1000 1100 900 3400 4400 9000 9000 2200 4400 9000  /* level 1 */
		850 1000 1100 750 3200 4200 8000 8000 2200 4200 8000  /* level 2 */
		850 1000 1100 650 2200 3400 7000 7000 1000 3400 7000  /* level 3 */
		700 1000 1100 650 1800 2800 6000 6000 1000 2800 6000  /* level 4 */
		700 1000  700 650 1500 2600 5000 5000  800 2600 5000  /* level 5 */
		500 1000  700 650 1300 2200 4000 4000  800 2200 4000  /* level 6 */
		500  700  600 400 1100 2200 3500 3500  700 2200 3500  /* level 7 */
		500  700  600 400 1000 1800 3000 3000  700 1800 3000  /* level 8 */
		500  500  500 300  800 1100 2500 2500  600 1100 2500  /* level 9 */
		400  500  500 300  700 1000 2000 2000  600 1000 2000  /* level 10 */
		400  500  500 250  600  800 1500 1500  500  800 1500  /* level 11 */
		400  500  500 250  500  700 1000 1000  500  700 1000  /* level 12 */
		300  500  500 250  500  600  800  800  400  600  800   /* level 13 */
		300  400  400 200  400  500  500  500  400  500  500   /* level 14 */
		300  300  300 150  300  300  300  300  300  300  300   /* level 15 */
	>;
};

&mca_buckchg_jeita {
	status = "ok";
	vterm_buffer = <40>;
	has-second-batt-para;
	support_weak_chg_vterm = <1>;
	weak_chg_vterm_cfg = <20 200>;
	has-global-batt-para;
	/* temp_low, temp_high, low_temp_hys, high_temp_hys, max_current, vterm, iterm volt_para_name */
	jeita_para =
		"-65535", "-10", "0", "2", "0", "4550", "81", "null",
		"-10", "-2", "0", "2", "326", "4550", "81", "para_n10_n2",
		"-2", "3", "0", "2", "407", "4550", "163", "para_n2_3",
		"3", "8", "0", "2", "652", "4550", "163", "para_3_8",
		"8", "13", "0", "2", "1629", "4560", "407", "para_8_13",
		"13", "15", "0", "1", "3258", "4560", "407", "para_13_15",
		"15", "18", "0", "1", "8960", "4560", "407", "para_15_18",
		"18", "23", "0", "1", "12218", "4550", "407", "null",
		"23", "25", "0", "0", "18300", "4550", "407", "null",
		"25", "35", "0", "0", "18300", "4550", "407", "null",
		"35", "40", "1", "0", "18300", "4520", "407", "null",
		"40", "48", "1", "0", "18300", "4510", "407", "null",
		"48", "55", "2", "0", "4073", "4080", "407", "null",
		"55", "65535", "2", "2", "0", "4080", "407", "null";
	para_n10_n2 =
		"3900", "326",
		"4550", "163";
	para_n2_3 =
		"3900", "407",
		"4550", "326";
	para_3_8 =
		"3900", "652",
		"4550", "407";
	para_8_13 =
		"3900", "1629",
		"4560", "815";
	para_13_15 =
		"3900", "3258",
		"4560", "1629";
	para_15_18 =
		"3900", "8960",
		"4150", "6516",
		"4250", "3258",
		"4560", "1629";
	jeita_para_ffc =
		"18", "23", "0", "1", "12218", "4580", "781", "null",
		"23", "25", "0", "0", "18300", "4580", "1064", "null",
		"25", "35", "0", "0", "18300", "4580", "1064", "null",
		"35", "40", "1", "0", "18300", "4580", "1751", "null",
		"40", "48", "1", "0", "18300", "4580", "3043", "null",
		"48", "55", "2", "0", "4073", "4080", "407", "null",
		"55", "65535", "2", "2", "0", "4080", "407", "null";
};

&mca_buckchg_jeita_second_para {
	/* temp_low, temp_high, low_temp_hys, high_temp_hys, max_current, vterm, iterm volt_para_name */
	jeita_para =
		"-65535", "-10", "0", "2", "0", "4530", "81", "null",
		"-10", "-2", "0", "2", "326", "4530", "81", "para_n10_n2",
		"-2", "3", "0", "2", "407", "4530", "163", "para_n2_3",
		"3", "8", "0", "2", "1222", "4540", "407", "para_3_8",
		"8", "13", "0", "2", "1629", "4540", "407", "para_8_13",
		"13", "15", "0", "1", "3258", "4540", "407", "para_13_15",
		"15", "18", "0", "1", "8960", "4540", "407", "para_15_18",
		"18", "23", "0", "1", "12218", "4520", "407", "null",
		"23", "25", "0", "0", "18300", "4520", "407", "null",
		"25", "35", "0", "0", "18300", "4520", "407", "null",
		"35", "40", "1", "0", "18300", "4500", "407", "null",
		"40", "48", "1", "0", "18300", "4490", "407", "null",
		"48", "55", "2", "0", "4073", "4080", "407", "null",
		"55", "65535", "2", "2", "0", "4080", "407", "null";
	para_n10_n2 =
		"3900", "326",
		"4530", "163";
	para_n2_3 =
		"3900", "407",
		"4530", "326";
	para_3_8 =
		"3900", "1222",
		"4540", "815";
	para_8_13 =
		"3900", "1629",
		"4540", "815";
	para_13_15 =
		"3900", "3258",
		"4540", "1629";
	para_15_18 =
		"3900", "8960",
		"4150", "6516",
		"4250", "3258",
		"4540", "1629";
	jeita_para_ffc =
		"18", "23", "0", "1", "12218", "4570", "977", "null",
		"23", "25", "0", "0", "17600", "4570", "1140", "null",
		"25", "35", "0", "0", "17600", "4570", "1140", "null",
		"35", "40", "1", "0", "17600", "4570", "1792", "null",
		"40", "48", "1", "0", "18300", "4570", "3095", "null",
		"48", "55", "2", "0", "4073", "4080", "407", "null",
		"55", "65535", "2", "2", "0", "4080", "407", "null";
};

&mca_buckchg_jeita_gbl_para {
	support_weak_chg_vterm = <1>;
	weak_chg_vterm_cfg = <10 200>;
	/* temp_low, temp_high, low_temp_hys, high_temp_hys, max_current, vterm, iterm volt_para_name */
	jeita_para =
		"-65535", "-10", "0", "2", "0", "4550", "309", "null",
		"-10", "3", "0", "2", "370", "4550", "309", "para_n10_3",
		"3", "8", "0", "2", "927", "4550", "432", "para_3_8",
		"8", "13", "0", "2", "1854", "4550", "432", "para_8_13",
		"13", "18", "0", "2", "3708", "4550", "432", "para_13_18",
		"18", "23", "0", "1", "12360", "4530", "432", "null",
		"23", "35", "0", "0", "18100", "4530", "432", "null",
		"35", "40", "1", "0", "18100", "4520", "432", "null",
		"40", "48", "1", "0", "18100", "4510", "432", "null",
		"48", "55", "2", "0", "3090", "4080", "432", "null",
		"55", "65535", "2", "2", "0", "4080", "432", "null";
	para_n10_3 =
		"4550", "370";
	para_3_8 =
		"4200", "927",
		"4550", "618";
	para_8_13 =
		"4200", "1854",
		"4550", "1236";
	para_13_18 =
		"4200", "3708",
		"4550", "2472";
	jeita_para_ffc =
		"18", "23", "0", "1", "12360", "4580", "1050", "null",
		"23", "35", "0", "0", "18100", "4580", "1668", "null",
		"35", "40", "1", "0", "18100", "4580", "2720", "null",
		"40", "48", "1", "0", "18100", "4580", "4264", "null",
		"48", "55", "2", "0", "3090", "4080", "432", "null",
		"55", "65535", "2", "2", "0", "4080", "432", "null";
};

&mca_nu1671_fod_data {
	/* type, length, uuid, params_no_mag, params_mag_thin, params_mag_thick */
	fod_params_default =
		"0", "12", "0x00000000", "params_default", "params_default", "params_default";
	params_default = /bits/ 8 <
		10  40
		10  40
		10  40
		8   47
		7   46
		7   53
		7   47
		7   49
		7   48
		7   46
		7   46
		7   46
	>;

	/* type, length, uuid, params_no_mag, params_mag_thin, params_mag_thick */
	fod_params_bpp_plus =
		"2", "7",  "0x00000000", "params_bpp_plus", "params_bpp_plus", "params_bpp_plus";
	params_bpp_plus = /bits/ 8 <
		10  50
		10  50
		8   50
		8   50
		8   50
		8   50
		8   50
	>;

	fod_params_2_1 =
		"1", "20", "0x09010A01", "params_m2_50W_2_1", "params_m2_50W_2_1", "params_m2_50W_2_1",
		"1", "20", "0x09010305", "params_n1_80W_2_1", "params_n1_80W_2_1", "params_n1_80W_2_1";
	/* gain, offset */
	params_m2_50W_2_1 = /bits/ 8 <
		0 27
		0 35
		0 30
		0 36
		0 36
		0 28
		0 6
		1 6
		1 7
		1 7
		1 5
		1 6
		2 6
		2 6
		2 11
		2 14
		2 28
		2 36
		2 36
		2 38
	>;

	params_n1_80W_2_1 = /bits/ 8 <
		0 18
		0 14
		0 11
		0 12
		0 11
		0 17
		0 14
		1 12
		1 16
		1 18
		1 20
		1 20
		2 16
		2 16
		2 20
		2 22
		2 25
		2 31
		2 31
		2 33
	>;


	/* type, length, uuid, params_no_mag, params_mag_thin, params_mag_thick */
	fod_params =
		"1", "20", "0x09010901", "params_l2_50W", "params_l2_50W", "params_l2_50W",
		"0", "12", "0x09010A01", "params_m2_50W", "params_m2_50W", "params_m2_50W",
		"1", "20", "0x09010904", "params_k1_80W", "params_k1_80W", "params_k1_80W",
		"1", "20", "0x0901090C", "params_k8_100W", "params_k8_100W", "params_k8_100W",
		"0", "12", "0x09010305", "params_n1_80W", "params_n1_80W", "params_n1_80W",
		"1", "20", "0x09010A07", "params_double_coil_30W", "params_double_coil_30W", "params_double_coil_30W",
		"2", "7",  "0x01020B03", "params_trx_rev_22P5W", "params_trx_rev_22P5W", "params_trx_rev_22P5W",
		"1", "20", "0x0901010B", "params_j1s_55W", "params_j1s_55W", "params_j1s_55W",
		"1", "20", "0x09080108", "params_zimi_20W", "params_zimi_20W", "params_zimi_20W",
		"1", "20", "0x07030801", "params_power_bank_30W", "params_power_bank_30W", "params_power_bank_30W",
		"1", "20", "0x09080607", "params_bluetooth_30W", "params_bluetooth_30W", "params_bluetooth_30W",
		"1", "20", "0x0C090908", "params_multcoil_20W", "params_multcoil_20W", "params_multcoil_20W",
		"1", "20", "0x09010407", "params_white_stand_30W", "params_white_stand_30W", "params_white_stand_30W",
		"1", "20", "0x06020801", "params_zimi_car_20W_2_1", "params_zimi_car_20W_2_1", "params_zimi_car_20W_2_1";

	params_l2_50W = /bits/ 8 <
		0 32
		0 29
		0 27
		0 26
		0 27
		0 28
		0 23
		1 23
		1 25
		1 25
		1 26
		1 29
		2 17
		2 20
		2 19
		2 10
		2 12
		2 10
		2 10
		2 38
	>;

	params_m2_50W = /bits/ 8 <
		10 40
		10 30
		10 67
		8  50
		7  14
		7  17
		7  19
		7  21
		7  18
		7  19
		7  22
		7  36
	>;
	params_trx_rev_22P5W = /bits/ 8 <
		10 2
		10 2
		8  255
		5  253
		4  253
		4  252
		4  252
	>;
	params_j1s_55W = /bits/ 8 <
		0 32
		0 29
		0 27
		0 26
		0 27
		0 28
		0 23
		1 23
		1 25
		1 25
		1 26
		1 29
		2 17
		2 20
		2 19
		2 10
		2 12
		2 10
		2 10
		2 38
	>;
	params_zimi_20W = /bits/ 8 <
		0 72
		0 58
		0 25
		0 27
		0 27
		0 29
		0 29
		1 30
		1 39
		1 39
		1 40
		1 62
		2 59
		2 64
		2 72
		2 75
		2 85
		2 95
		2 99
		2 101
	>;
	params_power_bank_30W = /bits/ 8 <
		0 32
		0 29
		0 27
		0 29
		0 27
		0 30
		0 28
		1 29
		1 25
		1 25
		1 26
		1 29
		2 30
		2 31
		2 30
		2 33
		2 29
		2 33
		2 26
		2 38
	>;
	params_bluetooth_30W = /bits/ 8 <
		0 32
		0 29
		0 27
		0 29
		0 27
		0 30
		0 28
		1 29
		1 25
		1 25
		1 26
		1 29
		2 30
		2 31
		2 30
		2 33
		2 29
		2 33
		2 26
		2 38
	>;
	params_multcoil_20W = /bits/ 8 <
		0 32
		0 29
		0 27
		0 29
		0 27
		0 30
		0 28
		1 29
		1 25
		1 25
		1 26
		1 29
		2 30
		2 31
		2 30
		2 33
		2 29
		2 33
		2 26
		2 38
	>;
	params_white_stand_30W = /bits/ 8 <
		0 37
		0 38
		0 28
		0 30
		0 31
		0 30
		0 31
		1 33
		1 29
		1 33
		1 40
		1 39
		2 36
		2 43
		2 37
		2 33
		2 38
		2 38
		2 38
		2 38
	>;

	params_k8_100W = /bits/ 8 <
		0 32
		0 31
		0 26
		0 26
		0 24
		0 28
		0 30
		1 29
		1 33
		1 37
		1 40
		1 41
		2 35
		2 39
		2 40
		2 43
		2 49
		2 55
		2 52
		2 91
	>;
	params_k1_80W = /bits/ 8 <
		0 32
		0 31
		0 26
		0 26
		0 24
		0 28
		0 30
		1 29
		1 33
		1 37
		1 40
		1 41
		2 35
		2 39
		2 40
		2 43
		2 49
		2 55
		2 56
		2 91
	>;
	params_k1_80W_mag = /bits/ 8 <
		0 77
		0 55
		0 53
		0 56
		0 55
		0 55
		0 60
		1 60
		1 63
		1 67
		1 77
		1 80
		2 80
		2 84
		2 90
		2 87
		2 92
		2 104
		2 110
		2 114
	>;

	params_n1_80W = /bits/ 8 <
		10 10
		10 0
		8  251
		0  2
		0  0
		0  1
		0  3
		0  4
		0  7
		0  7
		0  5
		0  5
	>;
	params_double_coil_30W = /bits/ 8 <
		0 40
		0 16
		0 22
		0 12
		0 26
		0 15
		0 18
		1 17
		1 23
		1 26
		1 32
		1 38
		2 40
		2 62
		2 64
		2 64
		2 64
		2 67
		2 67
		2 69
	>;
	params_zimi_car_20W_2_1 = /bits/ 8 <
		0 72
		0 58
		0 25
		0 27
		0 27
		0 29
		0 29
		1 30
		1 39
		1 39
		1 40
		1 62
		2 59
		2 64
		2 72
		2 75
		2 85
		2 95
		2 99
		2 101
	>;
};
&charger_partition {
	status = "ok";
};

&mca_vbat_ovp_mon {
	status = "ok";
	support_global_fv;
	vbat_ovp_threshold_ffc = <4580>;
	vbat_ovp_threshold_normal = <4560>;
	vbat_ovp_threshold_ffc_gl = <4580>;
	vbat_ovp_threshold_normal_gl = <4550>;
};

&soc {
	ut_test {
		compatible = "charge,ut-test";
		status = "ok";
		has-global-batt-para;

		mi,lossless_rechg_nvt_cn;
		mi,cycle_volt_nvt_cn = "0,100,4240,4290,4380,4500,4580,100,200,4190,4240,4360,4480,4540,200,300,4190,4240,4340,4460,4530,300,400,4190,4240,4320,4440,4530,400,800,4190,4240,4300,4420,4510,800,1000,4190,4240,4280,4400,4480,1000,1200,4190,4240,4260,4380,4480,1200,10000,4190,4240,4240,4360,4450";
		mi,cycle_step_curr_nvt_cn = "0,100,17600,12400,9774,8145,6516,100,200,17600,11160,8797,7331,5864,200,300,17600,10540,8308,6923,5539,300,400,17600,9920,7819,6516,5213,400,800,17600,9300,7331,6109,4887,800,1000,17600,8680,6842,5702,4561,1000,1200,17600,8680,6842,5702,4561,1200,10000,17600,8060,6353,5294,4235";
		mi,temp_term_curr_nvt_cn = "23,35,1064,35,40,1751,40,48,3043";
		mi,thermal_nvt_cn = "17600,13500,11000,9000,8000,7000,6000,5000,4000,3500,3000,2500,2000,1500,1000,500";

		mi,lossless_rechg_swd_cn;
		mi,cycle_volt_swd_cn = "0,30,4190,4270,4350,4500,4570,30,80,4190,4270,4350,4480,4550,80,180,4140,4220,4310,4460,4550,180,400,4140,4220,4290,4440,4540,400,800,4140,4220,4270,4420,4540,800,1000,4140,4220,4250,4400,4530,1000,1200,4140,4220,4230,4380,4480,1200,10000,4140,4220,4230,4360,4450";
		mi,cycle_step_curr_swd_cn= "0,30,17600,12400,9774,8145,6516,30,80,17600,12400,9774,8145,6516,80,180,17600,11160,8797,7331,5864,180,400,17600,10540,8308,6923,5539,400,800,17600,9920,7819,6516,5213,800,1000,17600,9300,7331,6109,4887,1000,1200,17600,8680,6842,5702,4561,1200,10000,17600,8060,6353,5294,4235";
		mi,temp_term_curr_swd_cn = "23,35,1222,35,40,1955,40,48,3258";
		mi,thermal_swd_cn = "17600,13500,11000,9000,8000,7000,6000,5000,4000,3500,3000,2500,2000,1500,1000,500";

		mi,lossless_rechg_nvt_global;
		mi,cycle_volt_nvt_global = "0,100,4230,4330,4400,4500,4570,100,300,4180,4300,4400,4480,4550,300,800,4180,4300,4400,4470,4540,800,10000,4180,4300,4400,4470,4520";
		mi,cycle_step_curr_nvt_global = "0,800,17600,12400,11124,9270,7416,800,10000,14080,9920,8899,7416,5932";
		mi,temp_term_curr_nvt_global = "23,35,1688,35,40,2720,40,48,4264";
		mi,thermal_nvt_global = "17600,13500,11000,9000,8000,7000,6000,5000,4000,3500,3000,2500,2000,1500,1000,500";
	};
};
